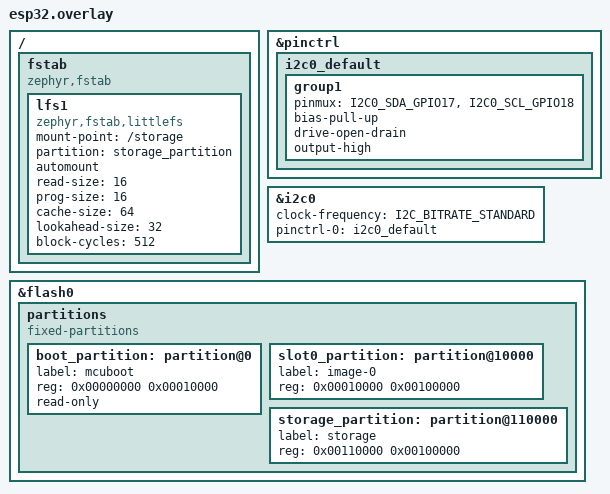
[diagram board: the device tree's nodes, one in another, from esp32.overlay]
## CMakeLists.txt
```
cmake_minimum_required(VERSION 3.20.0)
find_package(Zephyr REQUIRED HINTS $ENV{ZEPHYR_BASE})
project(meu_lora)

# Inclui o diretório de cabeçalhos
target_include_directories(app PRIVATE
    include
)

# # Subdiretórios
# add_subdirectory(src/federatedfearning)
# add_subdirectory(src/http)
# add_subdirectory(src/CJSON)
# add_subdirectory(src/websocket)

# add_subdirectory(src/espconfiguration)

# Adiciona os arquivos fonte do projeto
target_sources(app PRIVATE 
    src/main.c #problema com timer
    src/cJSON.c
    src/espconfiguration.c
    src/federatedlearning.c # log talvez e, float e double
    src/httpclient.c
    src/JSONConverter.c
    src/websocketclient.c
)
```

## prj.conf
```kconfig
# LORA
# CONFIG_LORA=y
# CONFIG_MAIN_STACK_SIZE=2048
# CONFIG_SYSTEM_WORKQUEUE_STACK_SIZE=2048

# LOG
CONFIG_LOG=y
CONFIG_LOG_DEFAULT_LEVEL=3

# pra usar printf
CONFIG_NEWLIB_LIBC=y
CONFIG_STDOUT_CONSOLE=y
CONFIG_PRINTK=y

# Wi-Fi Configuration
CONFIG_WIFI=y

CONFIG_WIFI_ESP32=y
CONFIG_WIFI_LOG_LEVEL_INF=y


# Network Configuration
CONFIG_NET_CONFIG_AUTO_INIT=n
CONFIG_NET_CONNECTION_MANAGER=y
CONFIG_NET_DHCPV4=y
CONFIG_NET_IF_MAX_IPV4_COUNT=2
CONFIG_NET_IPV4=y
CONFIG_NET_L2_ETHERNET=y
CONFIG_NET_L2_WIFI_MGMT=y
CONFIG_NET_MGMT=y
CONFIG_NET_MGMT_EVENT=y
CONFIG_NET_MGMT_EVENT_INFO=y
CONFIG_NET_MGMT_EVENT_QUEUE_SIZE=10
CONFIG_NET_MGMT_EVENT_STACK_SIZE=4096
CONFIG_NET_PKT_RX_COUNT=16
CONFIG_NET_PKT_TX_COUNT=16
CONFIG_NET_SOCKETS_SERVICE_STACK_SIZE=4096
CONFIG_NET_TCP=y
CONFIG_NET_UDP=y
CONFIG_NETWORKING=y

# LOG Configuration
CONFIG_NET_LOG=y
CONFIG_NET_DHCPV4_SERVER_LOG_LEVEL_DBG=y



# --- Rede básica ---
CONFIG_NET_IPV6=n
CONFIG_NET_SOCKETS=y


# --- Gerenciamento de rede ---
CONFIG_NET_MGMT=y
CONFIG_NET_MGMT_EVENT=y
CONFIG_NET_MGMT_EVENT_THREAD=y

# --- WebSocket & HTTP ---
CONFIG_HTTP_CLIENT=y
CONFIG_WEBSOCKET_CLIENT=y


# --- Gerenciamento de Memória e Stack ---
# Aumenta o Heap global para o k_malloc (Ajuste para 32KB, 64KB ou mais, dependendo do tamanho da sua rede neural)
CONFIG_HEAP_MEM_POOL_SIZE=65536 

# Aumenta a pilha da thread principal para lidar com a recursividade do cJSON e buffers de rede
CONFIG_MAIN_STACK_SIZE=8192

# --- Sistema de Arquivos (LittleFS) ---
CONFIG_FILE_SYSTEM=y
CONFIG_FILE_SYSTEM_LITTLEFS=y
CONFIG_FLASH=y
CONFIG_FLASH_MAP=y
CONFIG_FLASH_PAGE_LAYOUT=y

# --- Sensores e Barramentos ---
CONFIG_I2C=y

# --- Suporte a Ponto Flutuante (Floats) nos Logs ---
CONFIG_CBPRINTF_FP_SUPPORT=y

#===aaa
# --- Suporte a GPIO ---
CONFIG_GPIO=y

# --- Suporte Avançado de Wi-Fi ---
CONFIG_WIFI=y
CONFIG_NET_L2_WIFI_MGMT=y
CONFIG_WIFI_LOG_LEVEL_INF=y

# Degub
# CONFIG_WIFI_LOG_LEVEL_ERR=y
# CONFIG_NET_DHCPV4_LOG_LEVEL_DBG=y
# CONFIG_NET_IPV4_LOG_LEVEL_DBG=y
```

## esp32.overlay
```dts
/* Importa o dicionário de pinos do ESP32-S3 */
#include <zephyr/dt-bindings/pinctrl/esp32s3-pinctrl.h>

/* Importa o dicionário de velocidades do I2C (Resolve o erro do BITRATE) */
#include <zephyr/dt-bindings/i2c/i2c.h>

/ {
	/* 1. Configuração de Automount do Sistema de Arquivos */
	fstab {
		compatible = "zephyr,fstab";
		lfs1: lfs1 {
			compatible = "zephyr,fstab,littlefs";
			mount-point = "/storage";
			partition = <&storage_partition>;
			automount;
			read-size = <16>;
			prog-size = <16>;
			cache-size = <64>;
			lookahead-size = <32>;
			block-cycles = <512>;
		};
	};
};

/* 2. Mapeamento dos Pinos para o ESP32-S3 (Heltec V3) */
&pinctrl {
	i2c0_default: i2c0_default {
		group1 {
			/* Pinos I2C ajustados para o hardware da Heltec V3 */
			/* Se o seu sensor estiver em pinos diferentes, mude os números abaixo (ex: GPIO41) */
			pinmux = <I2C0_SDA_GPIO17>, <I2C0_SCL_GPIO18>;
			bias-pull-up;
			drive-open-drain;
			output-high;
		};
	};
};

/* 3. Ativação do Barramento I2C */
&i2c0 {
	status = "okay";
	clock-frequency = <I2C_BITRATE_STANDARD>; 
	pinctrl-0 = <&i2c0_default>;
	pinctrl-names = "default";
};

/* 4. Redefinição das Partições da Memória Flash */
/* 4. Redefinição das Partições da Memória Flash */
&flash0 {
	/delete-node/ partitions;
	partitions {
		compatible = "fixed-partitions";
		#address-cells = <1>;
		#size-cells = <1>;

		/* CORREÇÃO: O Bootloader do ESP32-S3 inicia obrigatoriamente em 0x0 */
		boot_partition: partition@0 {
			label = "mcuboot";
			reg = <0x00000000 0x00010000>;
			read-only;
		};

		/* Partição do seu código (lógica e RTOS) */
		slot0_partition: partition@10000 {
			label = "image-0";
			reg = <0x00010000 0x00100000>; /* 1 MB para o código */
		};

		/* Partição para o dataset.csv usando LittleFS */
		storage_partition: partition@110000 {
			label = "storage";
			reg = <0x00110000 0x00100000>; /* 1 MB de espaço para o CSV */
		};
	};
};
```

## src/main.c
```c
#include <stdio.h>

#include <zephyr/kernel.h>          // Substitui TUDO do FreeRTOS
#include <zephyr/fs/fs.h>           // Substitui o esp_spiffs.h
#include <zephyr/fs/littlefs.h>     // Sistema de arquivos recomendado para Flash
#include <zephyr/drivers/i2c.h>     // Substitui driver/i2c.h
#include <zephyr/sys/reboot.h>      // Provável substituto para funções do esp_system.h
#include <zephyr/net/net_ip.h>

#include "espconfiguration.h"
#include "httpclient.h"
#include "websocketclient.h"
#include "federatedlearning.h"
#include "JSONConverter.h"


// Defina o endereço I2C do INA219 (geralmente é 0x40)
#define INA219_ADDR 0x40

// Pinos I2C
#define SDA_PIN 21
#define SCL_PIN 22

void brink_error_led(int blink){

    for(int i=0;i<blink;i++){
        // gpio_set_level(LED_PIN_ERROR, 1);
        k_msleep(100);
        // gpio_set_level(LED_PIN_ERROR, 0);
    }
}

void node_register(){
    // gpio_set_level(LED_PIN_SYNC, 1);
    getregisternode();
    k_msleep(100);
    // gpio_set_level(LED_PIN_SYNC, 0);
}

int global_model_status(){
    int status=0;
    // gpio_set_level(LED_PIN_SYNC, 1);
    status=getglobalmodelstatus();
    k_msleep(50);
    // gpio_set_level(LED_PIN_SYNC, 0);
    k_msleep(50);
    return status;
}

FederatedLearning *global_model(){
    // gpio_set_level(LED_PIN_SYNC, 1);
    FederatedLearning *globalmodelinstance = getglobalmodel();
    // gpio_set_level(LED_PIN_SYNC, 0);
    if(globalmodelinstance==NULL){
        while (globalmodelinstance==NULL){
            printf("Json null\n");
            brink_error_led(2);
            // gpio_set_level(LED_PIN_SYNC, 1);
            globalmodelinstance = getglobalmodel();     
            // gpio_set_level(LED_PIN_SYNC, 0);
        }
    }else{
            printf("Json not null\n");
        
    }
    
    return globalmodelinstance;
}

void deep_learning(){

    int ctrl=0;

    while (1){
        if(global_model_status()){
            replaceNeuralNetwork(global_model());
            NeuralNetworkTraining();
            websocket_send_local_model();
        }else{
            k_msleep(4000);
        }
        ctrl++;
    }
}


void deep_learning_test(){
    if(global_model_status()){
        FederatedLearning *globalmodelinstance = getglobalmodel();
        printf("getmodel\n");
        replaceNeuralNetwork(globalmodelinstance);
        PrintNeuralNetwork(globalmodelinstance->neuralnetwork);
        NeuralNetworkTraining();
        FederatedLearning *FDI = getFederatedLearningInstance();
        PrintNeuralNetwork(FDI->neuralnetwork);
    }
}


void start_esp32_configuration(){

    // UARTConfiguration();
    GPIOConfiguration();
    WIFIConfiguration();
    // SPIFFSConfiguration();
    
    // gpio_set_level(LED_PIN_ERROR, 0);
    // gpio_set_level(LED_PIN_SYNC, 0);
    k_msleep(2000);

}

void start_federated_learning_system_button(){
    int startled = 0;
    /*while (gpio_get_level(BUTTON_PIN)){
        startled = ~startled;
        gpio_set_level(LED_PIN_WORKING, startled);
        k_msleep(250);
    }*/
    //gpio_set_level(LED_PIN_WORKING, 1);
}

int main(){
    printf("iniciou");
    start_esp32_configuration();
    printf("1");
    start_federated_learning_system_button();

    // Tenta pegar a ficha. Se retornar 0, significa que pegou com sucesso!
    if (k_sem_take(&wifi_connected_sem, K_SECONDS(15)) == 0) {
        printf("Acesso liberado! Iniciando comunicacao com o servidor...\n");
    } else {
        printf("ERRO FATAL: Timeout. O roteador nao forneceu o IP.\n");
        // Opcional: Você pode colocar um k_msleep aqui e reiniciar a placa (sys_reboot)
    }
    
    printf("enter noderegister\n");
    node_register();
    printf("pass noderegister\n");
    deep_learning();

    return 0;
}
```

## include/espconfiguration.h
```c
#ifndef _espconfiguration
#define _espconfiguration

/* * Todas as bibliotecas esp_* e driver/* foram removidas.
 * O Zephyr cuidará das dependências dentro dos arquivos .c
 */

// Pinos
#define LED_PIN_ERROR 12
#define LED_PIN_WORKING 14
#define LED_PIN_SYNC 27
#define BUTTON_PIN 26

extern struct k_sem wifi_connected_sem;

// Credenciais de Rede
#define WIFI_SSID       "Alves"
#define WIFI_PASSWORD   "O4pN71nV"

// Funções de inicialização restantes
void WIFIConfiguration(void);
void GPIOConfiguration(void);

#endif
```

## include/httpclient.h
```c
#ifndef _httpclient
#define _httpclient

#include <zephyr/net/http/client.h>
#include <zephyr/net/socket.h> 

#include "federatedlearning.h"
#include "JSONConverter.h"

#define MAX_RETRIES 3   
#define TIMEOUT_MS 1000 

// 1. Isolamos o IP e a Porta para criar a conexão TCP (Socket)
#define SERVER_IP "192.168.18.192"
#define SERVER_PORT 8888

// 2. Isolamos as Rotas (Paths) para o Cabeçalho HTTP
#define GET_GLOBAL_MODEL        "/api/getglobalmodel"
#define GET_GLOBAL_MODEL_STATUS "/api/checkglobalmodel"
#define GET_REGISTER_NODE       "/api/noderegister"
#define POST_GLOBAL_MODEL       "/api/postglobalmodel"

// 3. Assinaturas das funções (removendo os parâmetros do FreeRTOS)
FederatedLearning* getglobalmodel(void);
int getglobalmodelstatus(void);
void postglobalmodel(void);
void getregisternode(void);

// Alterado para void (sem o pvParameters do FreeRTOS)
void http_post_task(void);

#endif
```

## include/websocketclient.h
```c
#ifndef _websocketclient
#define _websocketclient

//#include "configs.c"

#define IP "192.168.18.192"

#define WEBSOCKET_SERVER "ws://"IP":8080/"

void websocket_send_local_model();

#endif
```

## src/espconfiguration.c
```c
#include <zephyr/kernel.h>
#include <zephyr/logging/log.h>
#include <zephyr/drivers/gpio.h>
#include <zephyr/net/net_if.h>
#include <zephyr/net/wifi_mgmt.h>
#include <zephyr/net/net_mgmt.h>
#include <zephyr/net/dhcpv4.h>

#include <string.h>

#include <stdint.h>

#include "espconfiguration.h" // Mantenha para seus defines (WIFI_SSID, LED_PIN_ERROR, etc.)

LOG_MODULE_REGISTER(SystemConfig, LOG_LEVEL_INF);

K_SEM_DEFINE(wifi_connected_sem, 0, 1);

/* Estruturas para "ouvir" os eventos de rede (Substitui o esp_event_handler) */
static struct net_mgmt_event_callback wifi_cb;
static struct net_mgmt_event_callback ipv4_cb;

/* Handler para eventos de conexão e desconexão do Wi-Fi */
static void handle_wifi_events(struct net_mgmt_event_callback *cb, uint64_t mgmt_event, struct net_if *iface)
{
    switch (mgmt_event) {
        case NET_EVENT_WIFI_CONNECT_RESULT:
            LOG_INF("WiFi conectado ...");
            net_dhcpv4_start(iface);
            break;
        case NET_EVENT_WIFI_DISCONNECT_RESULT:
            LOG_INF("WiFi perdeu a conexão ...");
            break;
    }
}

static void handle_ipv4_events(struct net_mgmt_event_callback *cb, uint64_t mgmt_event, struct net_if *iface)
{
    if (mgmt_event == NET_EVENT_IPV4_ADDR_ADD) {
        
        char ip_str[NET_IPV4_ADDR_LEN];
        
        // CORREÇÃO: Adicionamos o ".ipv4." antes do is_used e do address
        if (iface->config.ip.ipv4->unicast[0].ipv4.is_used) {
            
            net_addr_ntop(AF_INET, 
                          &iface->config.ip.ipv4->unicast[0].ipv4.address.in_addr, 
                          ip_str, sizeof(ip_str));
                          
            LOG_INF("Conectado! O Roteador nos deu o IP: %s", ip_str);
        } else {
            LOG_INF("Conectado, mas falha ao ler o texto do IP.");
        }
        
        // Libera a ficha (semáforo) para a função main() continuar
        k_sem_give(&wifi_connected_sem); 
    }
}

void WIFIConfiguration(void)
{
    LOG_INF("Iniciando configuração de rede...");

    // 1. Registra os callbacks de evento de rede
    net_mgmt_init_event_callback(&wifi_cb, handle_wifi_events, NET_EVENT_WIFI_CONNECT_RESULT | NET_EVENT_WIFI_DISCONNECT_RESULT);
    net_mgmt_add_event_callback(&wifi_cb);

    net_mgmt_init_event_callback(&ipv4_cb, handle_ipv4_events, NET_EVENT_IPV4_ADDR_ADD);
    net_mgmt_add_event_callback(&ipv4_cb);

    // 2. Prepara a estrutura de conexão
    struct net_if *iface = net_if_get_default();
    struct wifi_connect_req_params wifi_params = {0};

    wifi_params.ssid = WIFI_SSID;
    wifi_params.ssid_length = strlen(WIFI_SSID);
    wifi_params.psk = WIFI_PASSWORD;
    wifi_params.psk_length = strlen(WIFI_PASSWORD);
    wifi_params.channel = WIFI_CHANNEL_ANY;
    wifi_params.security = WIFI_SECURITY_TYPE_PSK; // Assumindo WPA2

    // 3. Solicita a conexão
    LOG_INF("Conectando ao WiFi...");
    if (net_mgmt(NET_REQUEST_WIFI_CONNECT, iface, &wifi_params, sizeof(struct wifi_connect_req_params))) {
        LOG_ERR("Erro ao solicitar conexão Wi-Fi.");
    }
}

void GPIOConfiguration(void)
{
    /* No ESP32, os pinos de 0 a 31 pertencem ao controlador "gpio0" */
    const struct device *gpio0 = DEVICE_DT_GET(DT_NODELABEL(gpio0));

    if (!device_is_ready(gpio0)) {
        LOG_ERR("Controlador GPIO não está pronto!");
        return;
    }

    // Configurar as saídas (LEDs) e já garantir que comecem desligadas (INACTIVE)
    gpio_pin_configure(gpio0, LED_PIN_ERROR, GPIO_OUTPUT_INACTIVE);
    gpio_pin_configure(gpio0, LED_PIN_WORKING, GPIO_OUTPUT_INACTIVE);
    gpio_pin_configure(gpio0, LED_PIN_SYNC, GPIO_OUTPUT_INACTIVE);

    // Configurar a entrada (Botão) com resistor interno de pull-up
    gpio_pin_configure(gpio0, BUTTON_PIN, GPIO_INPUT | GPIO_PULL_UP);

    LOG_INF("GPIOs configurados com sucesso.");
}
```

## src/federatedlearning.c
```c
#include <stdio.h>
#include <stdlib.h>
#include <math.h>
#include <time.h>
#include <string.h>

#include "federatedlearning.h"

#include <zephyr/logging/log.h>
#include <zephyr/kernel.h>

LOG_MODULE_REGISTER(FedLearning, LOG_LEVEL_INF);

//////////////////////////////////////////////////PRINT//////////////////////////////////////////////////

void teste(){
    printf("🐉\n");
}

void PrintNeuralNetwork(NeuralNetwork * neuralnetwork) {

  int i = 0, j = 0, k = 0;

  Layer * currentlayer = neuralnetwork -> firstlayer;
  while (currentlayer != NULL) {

    i++;
    printf("layer %d neurons: %d\n", i, currentlayer -> neurons);

    Neuron * currentneuron = currentlayer -> firstneuron;

    while (currentneuron != NULL) {

      j++;
      printf("%s neuron %d - weights: %d\n",currentneuron->neurontype , j,currentneuron -> weights);
      printf("Bias: %.10f\n",currentneuron->bias);

      Weight * currentweight = currentneuron -> firstweight;

      while (currentweight != NULL) {

        k++;
        printf("%d value: %.10f ", k, currentweight -> weight);

        currentweight = currentweight -> nextweight;
      }
      printf("\n");
      k = 0;
      currentneuron = currentneuron -> nextneuron;
    }
    j = 0;
    currentlayer = currentlayer -> nextlayer;

  }
  i = 0;
  printf("\n");

}

void printVector(float *data,int size){
  for(int i =0; i< size;i++){
    printf("%f ", data[i]);
  }
  printf("\n");
}

void printMatriz(float **data, int linhas, int colunas) {
    for (int i = 0; i < linhas; i++) {
        for (int j = 0; j < colunas; j++) {
            printf("%f ", data[i][j]);
        }
        printf("\n");
    }
}

//////////////////////////////////////////////////DEEPLEARNINGMATHFUNCTIONS//////////////////////////////////////////////////

float Perceptron(float Z){
    if(Z>0)
    {
      return 1;
    }
    else{
     return 0; 
    }
}

float PerceptronDerivative(float a){
    if(a>0){
      return 1;
    }
    else{
     return 0; 
    }
}

float ReLU(float Z){
  if(Z>0){
    return Z;
  }else{
    return 0;
  }
}

float ReLUDerivative(float a){
    if(a>0){
      return 1;
    }
    else{
     return 0; 
    }
}

float Sigmoid(float Z) {
  return 1.0 / (1.0 + exp(-Z));
}

float SigmoidDerivative(float a) {
  return a * (1 - a);
}

float SoftMax( float Z,float softmaxsum ){
  return exp(Z)/softmaxsum;
}

float SoftMaxDerivative1(float a){
  
  return a*(1-a);
}

float SoftMaxDerivative2(float a1 , float a2){
  
  return a1*a2;

}

float CategoricalCrossEntropyDerivative(float y, float a) {
  return -(y / a);
}

float CategoricalCrossEntropy(float * label, float * output, int labelsize) {
  float sum = 0;
  for (int i = 0; i < labelsize; i++) {
    sum += label[i] * log(output[i]);
  }
  return -sum;
}

//////////////////////////////////////////////////FREEALLOCATEDMEMORY//////////////////////////////////////////////////

void freeWeight(Weight *weight) {
    if(weight!=NULL){
        free(weight);        
    }
}

void freeNeuron(Neuron *neuron) {
    if(neuron!=NULL){
        free(neuron);        
    }
}

void freeLayer(Layer *layer) {
    if(layer!=NULL){
        free(layer);        
    }
}

void freeNeuralNetwork(NeuralNetwork *neuralnetwork) {
    //printf("teste 0");
    if(neuralnetwork==NULL){
        return;   
    }

    Layer *currentlayer = neuralnetwork->firstlayer;

    while (currentlayer != NULL) {
      //printf("teste 1");
        // Libere a memória dos neurônios na camada atual
        Neuron *currentneuron = currentlayer->firstneuron;
        while (currentneuron != NULL) {
            //printf("teste 2");

            // Libere a memória dos pesos associados ao neurônio atual
            Weight *currentweight = currentneuron->firstweight;
            while (currentweight != NULL) {
                //printf("teste 3");

                Weight *nextweight = currentweight->nextweight;
                freeWeight(currentweight);
                currentweight = nextweight;
            }

            // Libere a memória do neurônio atual
            Neuron *nextneuron = currentneuron->nextneuron;
            freeNeuron(currentneuron);
            currentneuron = nextneuron;
        }

        // Libere a memória da camada atual
        Layer *nextlayer = currentlayer->nextlayer;
        freeLayer(currentlayer);
        currentlayer = nextlayer;
    }

    free(neuralnetwork);
}

void freeFederatedLearning(FederatedLearning *federatedlearning){

  if(federatedlearning==NULL){
    return;
  }
  freeNeuralNetwork(federatedlearning->neuralnetwork);

}
void freeVector(float *vector) {
    if (vector != NULL) {
        free(vector);
    }
}

void freeMatrix(float **matrix, int lines) {
    if (matrix != NULL) {
        for (int i = 0; i < lines; i++) {
            if (matrix[i] != NULL) {
                free(matrix[i]);
            }
        }
        free(matrix);
    }
}

//////////////////////////////////////////////////DEEPLEARNINGNEURALNETWORK//////////////////////////////////////////////////

float ActivationFunctionCalculaton(NeuralNetwork *neuralnetwork,float Z, int activationfunctiontype){

  //printf("activaiton function type: %d",activationfunctiontype);

  Layer *currentlayer;
  Neuron *currentneuron, *previousneuron;
  Weight *currentweight;

  float sum = 0;
  float softmaxsum=0;

switch (activationfunctiontype)
{
case 1:
  return Perceptron(Z);
case 2:
  return ReLU(Z);
case 3:
  return Sigmoid(Z); 
case 4:

      currentlayer = neuralnetwork->lastlayer;
      currentneuron = currentlayer -> firstneuron;
      previousneuron = currentlayer->previouslayer->firstneuron;

      for (int i = 0; i < currentlayer -> neurons; i++) {
        currentweight= currentneuron->firstweight;
        //printf("wieghts %d \nB %f - ",currentneuron->weights,currentneuron->bias);
        sum+= currentneuron->bias;
        for (int j = 0;  j< currentneuron -> weights; j++) {
          sum += currentweight->weight * previousneuron->activationfunctionvalue;
          //printf("W %f IN %f - ",currentweight->weight,previousneuron->activationfunctionvalue,Z);
          currentweight =currentweight->nextweight;
          previousneuron = previousneuron ->nextneuron;
        }
        softmaxsum += exp(sum);

        sum = 0;
        currentneuron = currentneuron -> nextneuron;
        previousneuron = currentlayer->previouslayer->firstneuron;
      }
      //printf("Exp Z %f SOFTMAXSUM += %f\n",exp(Z),softmaxsum);

      return SoftMax(Z,softmaxsum);

default:
  return 0;
}

}

float ActivationFunctionDerivativeCalculation(float a, int activationfunctiontype){
  
switch (activationfunctiontype){

case 1:
  return PerceptronDerivative(a);
case 2:
  return ReLUDerivative(a);
case 3:
  return SigmoidDerivative(a); 
  
  default:
    return 0;
  }
}

float StochasticGradientDescentCalculation( float weight,float output ,float deltafunction,int regularization,float alpha,float lambda){

  switch (regularization){
    
    case 0:
      //printf("REGULATION 0 ");
      return -alpha * deltafunction * output;
    
    case 1:
      //printf("REGULATION 1 ");

      if(weight >0){
        return -alpha * (deltafunction * output + 1);

      }
      else if(weight==0){
        return -alpha * (deltafunction * output + 0);

      }
      else{
        return -alpha * (deltafunction * output -1);
        
      }
    case 2:
      //printf("REGULATION 2 ");

      return -alpha * (deltafunction * output + 2*lambda*weight);
      
    default:
      return 0;
  }
}

float RidgeRegressionCalculation(NeuralNetwork *neuralnetwork,float lambda){

  float sum=0;

  Layer *currentlayer;
  Neuron *currentneuron;
  Weight *currentweight;

  currentlayer = neuralnetwork->firstlayer; 
  while(currentlayer != NULL){
    currentneuron = currentlayer->firstneuron;

    while (currentneuron!=NULL){
      currentweight = currentneuron->firstweight;

      while (currentweight!=NULL){
        sum += currentweight->weight*currentweight->weight;
        currentweight = currentweight->nextweight;
      }
      currentneuron= currentneuron->nextneuron;
    }
      currentlayer = currentlayer->nextlayer;
  }
  return sum*lambda;
}

float LassoRegressionCalculation(NeuralNetwork *neuralnetwork,float lambda){
  
  float sum=0;

  Layer *currentlayer;
  Neuron *currentneuron;
  Weight *currentweight;

  currentlayer = neuralnetwork->firstlayer; 
  while(currentlayer != NULL){
    currentneuron = currentlayer->firstneuron;

    while (currentneuron!=NULL){
      currentweight = currentneuron->firstweight;

      while (currentweight!=NULL){

        if (currentweight->weight>=0){
          sum += currentweight->weight;
        }
        else{
          sum += -currentweight->weight;
        }

        currentweight = currentweight->nextweight;
      }
      currentneuron= currentneuron->nextneuron;
    }
      currentlayer = currentlayer->nextlayer;
  }
  return sum*lambda;
}

float LossFunctionCalculation(NeuralNetwork * neuralnetwork, float *labelvector, int regularization,float lambda){  
  
  float outputdata[neuralnetwork -> lastlayer->neurons];
  Neuron *currentneuron = neuralnetwork -> lastlayer -> firstneuron;
  //getting the neurons output value for loss function
  for (int i = 0; i < neuralnetwork->lastlayer->neurons; i++) {
    outputdata[i] = currentneuron -> activationfunctionvalue;
    currentneuron = currentneuron -> nextneuron;
    //printf("label %f output %f \n",labelvector[i],outputdata[i]);
  }

  switch (neuralnetwork->lossfunctiontype){
  case MINIMAL_MEAN_SQUARE:
    break;
  
  case CATEGORICAL_CROSS_ENTROPY:

    switch (regularization){
      
      case 0:
        return  CategoricalCrossEntropy(labelvector, outputdata, neuralnetwork->lastlayer->neurons) ;
      case 1:
        return  CategoricalCrossEntropy(labelvector, outputdata, neuralnetwork->lastlayer->neurons) + LassoRegressionCalculation(neuralnetwork,lambda);
      case 2:
        return  CategoricalCrossEntropy(labelvector, outputdata, neuralnetwork->lastlayer->neurons) + RidgeRegressionCalculation(neuralnetwork,lambda);
      default:
        break;
    }

    break;
  default:
    return 0;
  }

  return 0;
}

void FeedFoward(NeuralNetwork * neuralnetwork){

  Layer *currentlayer = neuralnetwork->firstlayer->nextlayer;
  Neuron *currentneuron;
  Weight *currentweight;
  
  //printf("FEEDFOWARD\n");

  for (int layer = 1; layer < neuralnetwork -> layers; layer++) {

    //printf("LAYER %d\n",layer);
            
    Neuron *previousneuron = currentlayer->previouslayer->firstneuron;
    currentneuron = currentlayer -> firstneuron;
    float Z = 0;
          
    //printf("neurons %d\n",currentlayer->neurons);

      for (int i = 0; i < currentlayer -> neurons; i++) {
        currentweight= currentneuron->firstweight;
        //printf("wieghts %d \nB %f - ",currentneuron->weights,currentneuron->bias);
        Z+= currentneuron->bias;
        for (int j = 0;  j< currentneuron -> weights; j++) {
          Z += currentweight->weight * previousneuron->activationfunctionvalue;
          //printf("W %f IN %f + ",currentweight->weight,previousneuron->activationfunctionvalue);
          currentweight =currentweight->nextweight;
          previousneuron = previousneuron ->nextneuron;
        }
        currentneuron -> activationfunctionvalue =  ActivationFunctionCalculaton(neuralnetwork,Z,currentlayer->activationfunctiontype);
        //printf("Z %f ATIVACAO %f\n",Z,currentneuron -> activationfunctionvalue);
        Z = 0;
        currentneuron = currentneuron -> nextneuron;
        previousneuron = currentlayer->previouslayer->firstneuron;
      }
    currentlayer = currentlayer -> nextlayer;
    }
}

void BackPropagation(NeuralNetwork *neuralnetwork, float *label, float alpha, int regularization, float lambda){
  //printf("BACKPROPAGATION\n");
      
  //aux memory 
  int  weightscolumn=0, weightslines=0, deltafunctionsnumber=0;
  float **weights = NULL;
  float *deltafunctions = NULL;
  // variables to cycle through pointers
  Layer * currentlayer = neuralnetwork -> firstlayer;
  Neuron * currentneuron = currentlayer -> firstneuron;
  Weight * currentweight;

  currentlayer = neuralnetwork -> lastlayer;
  for (int layer = neuralnetwork -> layers ; layer > 1; layer--) {

    //verify the last layer
    if (layer == neuralnetwork -> layers) {

      //printf("layer %d \n",layer);

      //allocate memory for delta functions
      deltafunctionsnumber = currentlayer->neurons;
      deltafunctions = (float * ) malloc(deltafunctionsnumber * sizeof(float));
      currentneuron = currentlayer -> firstneuron;

      for (int i = 0; i < currentlayer->neurons; i++) {
        deltafunctions[i] =  currentneuron->activationfunctionvalue - label[i];
        //printf("label %f output value %f delta %f\n",label[i],currentneuron -> activationfunctionvalue,deltafunctions[i]);
        currentneuron = currentneuron -> nextneuron;
      }

      //printf("\n");

      //alocate memory for weights matrix
      weightslines = currentlayer ->previouslayer -> neurons;
      weightscolumn = currentlayer->neurons;

      weights = (float ** ) malloc(weightslines * sizeof(float * ));

      for (int i = 0; i < currentlayer -> previouslayer -> neurons; i++) {
        weights[i] = (float * ) malloc(weightscolumn * sizeof(float));
      }

      currentneuron = currentlayer -> firstneuron;
      Neuron* previousneuron; 
          
      for (int i = 0; i < currentlayer->neurons; i++){  
        currentneuron->bias += - deltafunctions[i] * alpha;
        previousneuron = currentlayer->previouslayer->firstneuron;
        currentweight = currentneuron->firstweight;

        for(int j=0;j<currentlayer->previouslayer->neurons ;j++){
          //printf("W %f A %f ",currentweight->weight,previousneuron->activationfunctionvalue);
          //currentweight->weight +=  - deltafunctions[i] * previousneuron->activationfunctionvalue * alpha; 
          currentweight->weight += StochasticGradientDescentCalculation(currentweight->weight,previousneuron->activationfunctionvalue,deltafunctions[i],regularization,alpha,lambda);
          //printf("D %f Wn %f\n",deltafunctions[i],currentweight->weight);
          weights[j][i] = currentweight -> weight;
          previousneuron =previousneuron->nextneuron;
          currentweight = currentweight->nextweight;
        }
        currentneuron = currentneuron->nextneuron;
      }

    } 
    else{

      //printf("layer %d \n",layer);
      float * deltafunctionsaux = (float * ) malloc(deltafunctionsnumber * sizeof(float));
      memcpy(deltafunctionsaux, deltafunctions, deltafunctionsnumber * sizeof(float));
      deltafunctions = (float * ) k_realloc(deltafunctions, currentlayer->neurons * sizeof(int));
          
      float deltafunctionaccumulation;

      //calculatting delta
      currentneuron = currentlayer->firstneuron;
      for (int i = 0; i < weightslines; i++) {
        deltafunctionaccumulation = 0;
        for (int j = 0; j < weightscolumn; j++) {
          //printf("Dn %d D %f * W %f \n",j, deltafunctionsaux[j], weights[i][j]);
          deltafunctionaccumulation += deltafunctionsaux[j] * weights[i][j];
        }
          
        deltafunctions[i] = deltafunctionaccumulation *  ActivationFunctionDerivativeCalculation(currentneuron->activationfunctionvalue,currentlayer->activationfunctiontype);
        //printf("A %f Dn%i %f\n",currentneuron->activationfunctionvalue,i, deltafunctions[i]);            
        currentneuron = currentneuron->nextneuron;
      }

      freeMatrix(weights,weightslines);

      weightscolumn = weightslines;
      weightslines = currentlayer -> previouslayer -> neurons;
      deltafunctionsnumber = weightslines;
          
      //printf("wl %d wc %d\n",weightslines,weightscolumn);
          
      weights = (float ** ) malloc(weightslines * sizeof(float * ));          
      for (int i = 0; i < weightslines; i++) {
        weights[i] = (float * ) malloc(weightscolumn * sizeof(float));
      }

      currentneuron = currentlayer->firstneuron;
      Neuron *previousneuron;
          
      for(int i = 0; i< currentlayer->neurons;i++){            
        currentneuron->bias += - deltafunctions[i]*alpha;
        currentweight = currentneuron->firstweight;
        previousneuron = currentlayer->previouslayer->firstneuron;
        for (int j = 0; j < currentneuron->weights; j++){
          //printf("W %f D %f A %f GW %f",currentweight->weight,deltafunctions[i],previousneuron->activationfunctionvalue,- deltafunctions[i]*previousneuron->activationfunctionvalue*LearningRate);
          currentweight->weight +=  StochasticGradientDescentCalculation(currentweight->weight,previousneuron->activationfunctionvalue,deltafunctions[i],regularization,alpha,lambda); 
          //currentweight->weight +=  - deltafunctions[i] * previousneuron->activationfunctionvalue * alpha; 
          weights[j][i] = currentweight->weight;
          //printf(" Wn %f \n",currentweight->weight);
          currentweight = currentweight->nextweight;
          previousneuron = previousneuron->nextneuron;
        }
        //printf("\n");            
        currentneuron = currentneuron -> nextneuron;
      }
      //printMatriz(weights,weightslines,weightscolumn);
      freeVector(deltafunctionsaux);
    }
    currentlayer = currentlayer -> previouslayer;
  }

  freeMatrix(weights,weightslines);
  freeVector(deltafunctions);
}

void NeuralNetworkTraining() {

  FederatedLearning *federatedlearninginstance = getFederatedLearningInstance();
  NeuralNetwork * neuralnetwork = federatedlearninginstance->neuralnetwork;

  float trainingsample[neuralnetwork->firstlayer->neurons + neuralnetwork->lastlayer->neurons];
  float label[neuralnetwork->lastlayer->neurons];
  float Error = 0.0;

  FILE * file = NULL;
  char line[1024];
  Neuron * currentneuron = NULL;
  
  for (int TrainingCycle = 0; TrainingCycle < neuralnetwork->epoch; TrainingCycle++) {

    file = fopen("/storage/dataset.csv", "r");

    if (file == NULL) {
        LOG_ERR("Error when opening CSV file.");
        return;
    }

    for(int count =0; count < neuralnetwork->percentualtraining; count++){
      
      fgets(line, sizeof(line), file);

        char * token = strtok(line, ","); 

        for (int i = 0; i < 7; i++){
            token = strtok(NULL, ",");
            if (token != NULL) {
              trainingsample[i] = strtof(token, NULL);
            } else {
            LOG_ERR("Error: Not enought data in the line.\n");
            break;
            }
        }


      //set the input data on inputdata vector
      //printVector(trainingsample,7);

      currentneuron =  neuralnetwork->firstlayer->firstneuron;
      for (int i = 0; i < neuralnetwork->firstlayer->neurons; i++) {
        currentneuron -> activationfunctionvalue = trainingsample[i];
        currentneuron = currentneuron -> nextneuron;
      }

      //set the label on label vector
      for (int i = neuralnetwork->firstlayer->neurons; i < neuralnetwork->firstlayer->neurons + neuralnetwork->lastlayer->neurons; i++) {
        label[i - neuralnetwork->firstlayer->neurons] = trainingsample[i];
      }

      FeedFoward(neuralnetwork);
      Error = LossFunctionCalculation(neuralnetwork,label,neuralnetwork->regularization,neuralnetwork->lambda);
      BackPropagation(neuralnetwork,label,neuralnetwork->alpha,neuralnetwork->regularization,neuralnetwork->lambda);

      //printf("Loss: %f\n",Error);


    //size_t free_heap = heap_caps_get_free_size(MALLOC_CAP_8BIT);
    //printf("Free Heap Size: %u bytes\n", free_heap);

    }

    // Fecha o arquivo
    fclose(file);

    printf("Epoch %d Loss: %f\n",TrainingCycle+1,Error);
    
    //fprintf(arquivo,"%d %f\n", TrainingCycle+1,Error);

  }

    federatedlearninginstance->trainingscounter =  federatedlearninginstance->neuralnetwork->epoch * federatedlearninginstance->neuralnetwork->percentualtraining;

    //fclose(arquivo);
}

//////////////////////////////////////////////////FEDERATEDLEARNING//////////////////////////////////////////////////

void replaceNeuralNetwork(FederatedLearning * newfederatedlearninginstance){
    FederatedLearning * federatedlearninginstance =  getFederatedLearningInstance();
    memcpy(federatedlearninginstance->neuralnetwork, newfederatedlearninginstance->neuralnetwork, sizeof(NeuralNetwork));
    federatedlearninginstance->trainingscounter=0;
    //freeFederatedLearning(federatedlearninginstance);
}

void mergeNeuralNetwork(FederatedLearning * newfederatedlearninginstance){
//fazendo nd sei la pq, mas n chama ent ta d boa
}

FederatedLearning *getFederatedLearningInstance() {
    
    static FederatedLearning instance;
    if (instance.neuralnetwork == NULL) {
        instance.neuralnetwork = (NeuralNetwork *)malloc(sizeof(NeuralNetwork));
        instance.globalmodelstatus = 0;
        instance.trainingscounter = 0;
    }
    return &instance;
}

void readCSVFile() {

  float trainingsample[7];

  FILE * file = NULL;
  char line[1024];


    file = fopen("/storage/dataset.csv", "r");

    if (file == NULL) {
        LOG_ERR("Erro ao abrir o arquivo");
        return;
    }

    while (fgets(line, sizeof(line), file) != NULL) {


        char * token = strtok(line, ","); 

        for (int i = 0; i < 7; i++){
            token = strtok(NULL, ",");
            if (token != NULL) {
              trainingsample[i] = strtof(token, NULL);
            } else {
            LOG_ERR("Erro: Não há dados suficientes para preencher InputData na linha.\n");
            break;
            }
        }

      printf("InputData: [%.1f, %.1f, %.1f, %.1f, %.1f, %.1f, %.1f]\n", trainingsample[0], trainingsample[1], trainingsample[2], trainingsample[3], trainingsample[4], trainingsample[5], trainingsample[6]);


  }

}
```

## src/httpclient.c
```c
#include <zephyr/kernel.h>
#include <zephyr/logging/log.h>
#include <zephyr/net/socket.h>
#include <zephyr/net/http/client.h>
#include <stdlib.h>
#include <string.h>

#include "httpclient.h"
#include "cJSON.h"
#include "JSONConverter.h"
#include "federatedlearning.h"

LOG_MODULE_REGISTER(HTTP_CLIENT, LOG_LEVEL_INF);

/* * ATENÇÃO: No Zephyr, precisamos separar o IP e a porta da rota HTTP.
 * Configure estes valores no seu httpclient.h ou aqui mesmo:
 */
#ifndef SERVER_IP
#define SERVER_IP "192.168.18.192"
#define SERVER_PORT 8888
#endif

// Timeout e Retentativas
#define TIMEOUT_MS 5000
#define MAX_RETRIES 3

// Variáveis globais para armazenar a resposta HTTP
static char *response_buffer = NULL;
static size_t response_buffer_length = 0;

// Funções utilitárias (Mantidas intactas!)
int is_utf8(const char *str) {
    while (*str) {
        if ((*str & 0x80) == 0) { str++; } 
        else if ((*str & 0xE0) == 0xC0) { if ((str[1] & 0xC0) != 0x80) return 0; str += 2; } 
        else if ((*str & 0xF0) == 0xE0) { if ((str[1] & 0xC0) != 0x80 || (str[2] & 0xC0) != 0x80) return 0; str += 3; } 
        else if ((*str & 0xF8) == 0xF0) { if ((str[1] & 0xC0) != 0x80 || (str[2] & 0xC0) != 0x80 || (str[3] & 0xC0) != 0x80) return 0; str += 4; } 
        else { return 0; }
    }
    return 1;
}

int is_complete_json(const char *json, size_t len) {
    int count_open_braces = 0;
    int count_close_braces = 0;
    for (size_t i = 0; i < len; ++i) {
        if (json[i] == '{') count_open_braces++;
        else if (json[i] == '}') count_close_braces++;
    }
    return (count_open_braces == count_close_braces && count_open_braces > 0);
}

// Callback interno do Zephyr para montar o JSON em pedaços
static void http_response_cb(struct http_response *rsp,
                             enum http_final_call final_data,
                             void *user_data)
{
    if (rsp->data_len > 0) {
        char *new_buf = realloc(response_buffer, response_buffer_length + rsp->data_len + 1);
        if (new_buf == NULL) {
            LOG_ERR("Falha ao alocar memória para o buffer de resposta");
            return;
        }
        response_buffer = new_buf;
        memcpy(response_buffer + response_buffer_length, rsp->recv_buf, rsp->data_len);
        response_buffer_length += rsp->data_len;
        response_buffer[response_buffer_length] = '\0'; // Garante o final da string
    }
}

// O motor principal de requisições HTTP do nosso Zephyr
static int perform_http_request(enum http_method method, const char *path, const char *payload)
{
    int sock;
    struct sockaddr_in server_addr;
    struct http_request req;
    int ret;
    int retries = 0;
    
    // Buffer temporário que o Zephyr usa para ler os pacotes TCP da rede
    uint8_t internal_rx_buf[1024];

    // Limpa o buffer de resposta global antes de cada requisição
    if (response_buffer != NULL) {
        free(response_buffer);
        response_buffer = NULL;
    }
    response_buffer_length = 0;

    // Configura o endereço do servidor
    server_addr.sin_family = AF_INET;
    server_addr.sin_port = htons(SERVER_PORT);
    zsock_inet_pton(AF_INET, SERVER_IP, &server_addr.sin_addr);

    while (retries < MAX_RETRIES) {
        int64_t start_time = k_uptime_get(); // Relógio interno do Zephyr

        sock = zsock_socket(AF_INET, SOCK_STREAM, IPPROTO_TCP);
        if (sock < 0) {
            LOG_ERR("Falha ao criar socket TCP");
            retries++;
            k_msleep(1000);
            continue;
        }

        ret = zsock_connect(sock, (struct sockaddr *)&server_addr, sizeof(server_addr));
        if (ret < 0) {
            LOG_ERR("Falha ao conectar no servidor");
            zsock_close(sock);
            retries++;
            k_msleep(1000);
            continue;
        }

        memset(&req, 0, sizeof(req));
        req.method = method;
        req.url = path;
        req.host = SERVER_IP;
        req.protocol = "HTTP/1.1";
        req.response = http_response_cb; // Associa nosso callback
        req.recv_buf = internal_rx_buf;
        req.recv_buf_len = sizeof(internal_rx_buf);

        if (payload != NULL) {
            req.payload = payload;
            req.payload_len = strlen(payload);
            const char *headers[] = {"Content-Type: application/json\r\n", NULL};
            req.header_fields = headers;
        }

        // A mágica acontece aqui!
        ret = http_client_req(sock, &req, TIMEOUT_MS, NULL);

        zsock_close(sock); // Sempre feche o socket após usar

        if (ret >= 0) {
            int64_t elapsed_time = k_uptime_get() - start_time;
            LOG_INF("Requisição feita com sucesso. Latência: %lld ms", elapsed_time);
            return 0; // Sucesso
        } else {
            LOG_ERR("Erro ao enviar a requisição: %d", ret);
        }

        int64_t current_time = k_uptime_get();
        if ((current_time - start_time) > TIMEOUT_MS) {
            LOG_WRN("Timeout alcançado, tentando novamente... (tentativa: %d)", retries + 1);
        }
        retries++;
    }

    LOG_ERR("Falha após %d tentativas", MAX_RETRIES);
    return -1; // Falha
}


////////////////////////////////////////////////// GETs //////////////////////////////////////////////////

int getglobalmodelstatus() {
    // ATENÇÃO: Substitua "/api/status" pela rota real que você usava no GET_GLOBAL_MODEL_STATUS
    perform_http_request(HTTP_GET, GET_GLOBAL_MODEL_STATUS, NULL);
    
    int status = 0;
    if (response_buffer != NULL) {
        cJSON *req = cJSON_Parse(response_buffer);
        if (req != NULL) {
            cJSON *status_item = cJSON_GetObjectItem(req, "status");
            if (status_item != NULL && cJSON_IsNumber(status_item)) {
                status = status_item->valueint;
            } else {
                LOG_ERR("Erro ao pegar 'status' ou não é um número.");
            }
            cJSON_Delete(req);
        } else {
            LOG_ERR("Falha no parse do JSON.");
        }
        free(response_buffer);
        response_buffer = NULL;
    }
    return status;
}

void getregisternode() {
    // ATENÇÃO: Substitua "/api/register" pela rota real
    perform_http_request(HTTP_GET, GET_REGISTER_NODE, NULL);
    printf("%c AAA", response_buffer);
    if (response_buffer != NULL) {
        cJSON *req = cJSON_Parse(response_buffer);
        if (req != NULL) {
            char *json_string = cJSON_Print(req);
            if (json_string != NULL) {
                printf("Node Registrado: %s\n", json_string);
                cJSON_free(json_string); // Usando cJSON_free para manter a integridade do heap
            }
            cJSON_Delete(req);
        }
        free(response_buffer);
        response_buffer = NULL;
    }
}

FederatedLearning *getglobalmodel() {
    // ATENÇÃO: Substitua "/api/model" pela rota real
    perform_http_request(HTTP_GET, GET_GLOBAL_MODEL, NULL);

    FederatedLearning *FederatedLearningInstance = NULL;
    if (response_buffer != NULL) {
        LOG_INF("Memória livre pré-Parse: %d", k_mem_slab_num_free_get(NULL)); // Log Zephyr
        cJSON *req = cJSON_Parse(response_buffer);
        
        if (req != NULL) {
            FederatedLearningInstance = JSONToFederatedLearning(req);
            cJSON_Delete(req);
        } else {
            LOG_ERR("Falha no parse do modelo global");
        }
        free(response_buffer);
        response_buffer = NULL;
    }
    return FederatedLearningInstance;
}


////////////////////////////////////////////////// POST //////////////////////////////////////////////////

// A sua antiga `http_post_task` agora é super limpa!
void http_post_task(void) {
    const char *post_data = "{\"key\":\"TESTEPOST\",\"value\":1}";
    
    LOG_INF("Iniciando POST de teste...");
    int ret = perform_http_request(HTTP_POST, "/api/testpost", post_data);
    
    if (ret == 0) {
        LOG_INF("POST de teste enviado com sucesso e resposta recebida!");
        if (response_buffer != NULL) {
            LOG_INF("Resposta do servidor: %s", response_buffer);
        }
    } else {
        LOG_ERR("Falha catastrófica no POST.");
    }
    
    // Thread encerra naturalmente no Zephyr ao chegar no fim da função
}
```

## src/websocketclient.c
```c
#include <stdio.h>
#include <string.h>
#include <zephyr/kernel.h>
#include <zephyr/logging/log.h>
#include <zephyr/net/socket.h>
#include <zephyr/net/websocket.h>

#include "websocketclient.h"
#include "cJSON.h"
#include "JSONConverter.h"
#include "federatedlearning.h"

/* No Zephyr, registramos o módulo de log assim, sem precisar passar a TAG nos prints */
LOG_MODULE_REGISTER(WebSocketClient, LOG_LEVEL_INF);

#define WS_SERVER_IP "192.168.18.192"
#define WS_SERVER_PORT 8080
#define WS_SERVER_PATH "/ws"

void websocket_send_local_model(void)
{
    int sock;
    int ws_sock;
    struct sockaddr_in server_addr;
    int ret;

    LOG_INF("Iniciando conexão com %s:%d ...", WS_SERVER_IP, WS_SERVER_PORT);

    // 1. Configurar o endereço do servidor (Socket padrão)
    server_addr.sin_family = AF_INET;
    server_addr.sin_port = htons(WS_SERVER_PORT);
    zsock_inet_pton(AF_INET, WS_SERVER_IP, &server_addr.sin_addr);

    // 2. Criar e conectar o socket TCP base
    sock = zsock_socket(AF_INET, SOCK_STREAM, IPPROTO_TCP);
    if (sock < 0) {
        LOG_ERR("Falha ao criar socket TCP: %d", errno);
        return;
    }

    ret = zsock_connect(sock, (struct sockaddr *)&server_addr, sizeof(server_addr));
    if (ret < 0) {
        LOG_ERR("Falha ao conectar via TCP: %d", errno);
        zsock_close(sock);
        return;
    }

    // 3. Promover o socket TCP para WebSocket (Handshake)
    struct websocket_request req = {
        .host = WS_SERVER_IP,
        .url = WS_SERVER_PATH,
    };

    ws_sock = websocket_connect(sock, &req, 5000, NULL); // 5 segundos de timeout
    if (ws_sock < 0) {
        LOG_ERR("Falha no handshake WebSocket: %d", ws_sock);
        zsock_close(sock);
        return;
    }

    LOG_INF("WEBSOCKET_EVENT_CONNECTED");

    // 4. Gerar o JSON da rede neural (sua lógica original mantida!)
    cJSON *root = federatedLearningToJSON(getFederatedLearningInstance());
    if (root == NULL) {
        LOG_ERR("Falha ao criar JSON do modelo.");
        websocket_disconnect(ws_sock);
        zsock_close(sock);
        return;
    }

    char *json_string = cJSON_PrintUnformatted(root);
    cJSON_Delete(root);   // Corrige o vazamento da árvore JSON

    // 5. Enviar os dados via WebSocket
    if (json_string != NULL) {
        LOG_INF("Enviando modelo local (%d bytes)...", strlen(json_string));
        
        // portMAX_DELAY vira K_FOREVER no Zephyr
        ret = websocket_send_msg(ws_sock, json_string, strlen(json_string),
                                 WEBSOCKET_OPCODE_DATA_TEXT, true, true, SYS_FOREVER_MS);
        
        if (ret < 0) {
            LOG_ERR("Falha ao enviar os dados: %d", ret);
        } else {
            LOG_INF("Dados enviados com sucesso!");
        }

        // IMPORTANTE: Use cJSON_free em vez de free() normal para respeitar o Zephyr Heap
        cJSON_free(json_string);
    }

    // 6. Encerrar a conexão
    websocket_disconnect(ws_sock);
    zsock_close(sock);
    
    LOG_INF("Websocket Stopped");
}
```
